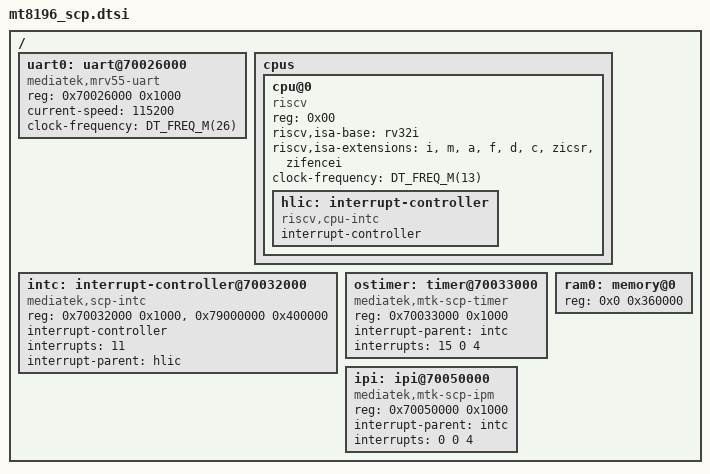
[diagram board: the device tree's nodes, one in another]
/*
 * SPDX-FileCopyrightText: Copyright (c) 2026 Mediatek
 *
 * SPDX-License-Identifier: Apache-2.0
 */


/dts-v1/;

#include <freq.h>

/ {
	#address-cells = < 0x01 >;
	#size-cells = < 0x01 >;

	uart0: uart@70026000 {
		compatible = "mediatek,mrv55-uart";
		reg = <0x70026000 0x1000>;
		current-speed = <115200>;
		clock-frequency = <DT_FREQ_M(26)>;
	};
	cpus {
		#address-cells = < 0x01 >;
		#size-cells = < 0x00 >;

		cpu@0 {
			device_type = "cpu";
			reg = < 0x00 >;
			status = "okay";
			compatible = "riscv";
			riscv,isa-base = "rv32i";
			riscv,isa-extensions = "i", "m", "a", "f", "d", "c", "zicsr", "zifencei";
			clock-frequency = <DT_FREQ_M(13)>;

			hlic: interrupt-controller {
				compatible = "riscv,cpu-intc";
				#address-cells = <0>;
				#interrupt-cells = <1>;
				interrupt-controller;
			};
		};

	};

	intc: interrupt-controller@70032000 {
		compatible = "mediatek,scp-intc";
		reg = <0x70032000 0x1000>, <0x79000000 0x400000>;
		reg-names = "intc", "plic";
		#address-cells = <1>;
		#size-cells = <0>;
		interrupt-controller;
		#interrupt-cells = <3>;
		interrupts = <11>;
		interrupt-parent = <&hlic>;
	};

	ostimer: timer@70033000 {
		compatible = "mediatek,mtk-scp-timer";
		reg = <0x70033000 0x1000>;
		interrupt-parent = <&intc>;
		interrupts = <15 0 4>;
	};

	ram0: memory@0 {
		device_type = "memory";
		reg = <0x0 0x360000>;
	};

	ipi: ipi@70050000 {
		compatible = "mediatek,mtk-scp-ipm";
		reg = <0x70050000 0x1000>;
		interrupt-parent = <&intc>;
		interrupts = <0 0 4>;
	};
};
